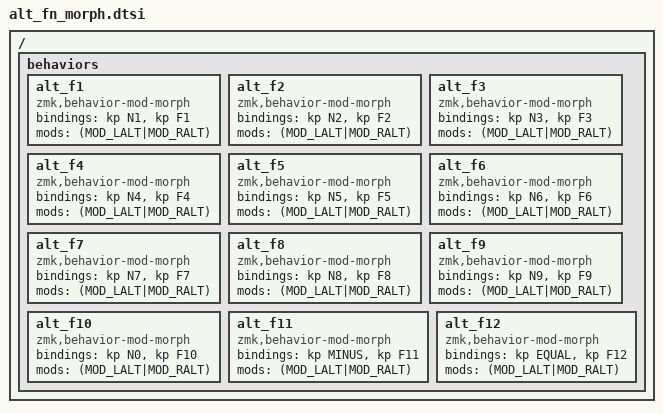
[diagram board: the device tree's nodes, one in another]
/ {
    behaviors {
        alt_f1: alt_f1 {
            compatible = "zmk,behavior-mod-morph";
            bindings = <&kp N1>, <&kp F1>;
            #binding-cells = <0>;
            mods = <(MOD_LALT|MOD_RALT)>;
        };

        alt_f2: alt_f2 {
            compatible = "zmk,behavior-mod-morph";
            bindings = <&kp N2>, <&kp F2>;
            #binding-cells = <0>;
            mods = <(MOD_LALT|MOD_RALT)>;
        };

        alt_f3: alt_f3 {
            compatible = "zmk,behavior-mod-morph";
            bindings = <&kp N3>, <&kp F3>;
            #binding-cells = <0>;
            mods = <(MOD_LALT|MOD_RALT)>;
        };

        alt_f4: alt_f4 {
            compatible = "zmk,behavior-mod-morph";
            bindings = <&kp N4>, <&kp F4>;
            #binding-cells = <0>;
            mods = <(MOD_LALT|MOD_RALT)>;
        };

        alt_f5: alt_f5 {
            compatible = "zmk,behavior-mod-morph";
            bindings = <&kp N5>, <&kp F5>;
            #binding-cells = <0>;
            mods = <(MOD_LALT|MOD_RALT)>;
        };

        alt_f6: alt_f6 {
            compatible = "zmk,behavior-mod-morph";
            bindings = <&kp N6>, <&kp F6>;
            #binding-cells = <0>;
            mods = <(MOD_LALT|MOD_RALT)>;
        };

        alt_f7: alt_f7 {
            compatible = "zmk,behavior-mod-morph";
            bindings = <&kp N7>, <&kp F7>;
            #binding-cells = <0>;
            mods = <(MOD_LALT|MOD_RALT)>;
        };

        alt_f8: alt_f8 {
            compatible = "zmk,behavior-mod-morph";
            bindings = <&kp N8>, <&kp F8>;
            #binding-cells = <0>;
            mods = <(MOD_LALT|MOD_RALT)>;
        };

        alt_f9: alt_f9 {
            compatible = "zmk,behavior-mod-morph";
            bindings = <&kp N9>, <&kp F9>;
            #binding-cells = <0>;
            mods = <(MOD_LALT|MOD_RALT)>;
        };

        alt_f10: alt_f10 {
            compatible = "zmk,behavior-mod-morph";
            bindings = <&kp N0>, <&kp F10>;
            #binding-cells = <0>;
            mods = <(MOD_LALT|MOD_RALT)>;
        };

        alt_f11: alt_f11 {
            compatible = "zmk,behavior-mod-morph";
            bindings = <&kp MINUS>, <&kp F11>;
            #binding-cells = <0>;
            mods = <(MOD_LALT|MOD_RALT)>;
        };

        alt_f12: alt_f12 {
            compatible = "zmk,behavior-mod-morph";
            bindings = <&kp EQUAL>, <&kp F12>;
            #binding-cells = <0>;
            mods = <(MOD_LALT|MOD_RALT)>;
        };
    };
};
